# LPC865 register map
Vendor: nxp.com; File version: 1.0
CPU: CM0PLUS r0p0, little endian, no MPU, no FPU, VTOR, 2 interrupt priority bits
Registers are 32-bit, read-write, reset 0x0 unless marked. A register's access mark holds for its fields unless they carry their own. Offsets are from the block's base; [hi:lo] are bit positions.

## USART0 — LPC84x USARTs
Base 0x40064000
Same registers: USART1 0x40068000, USART2 0x4006C000
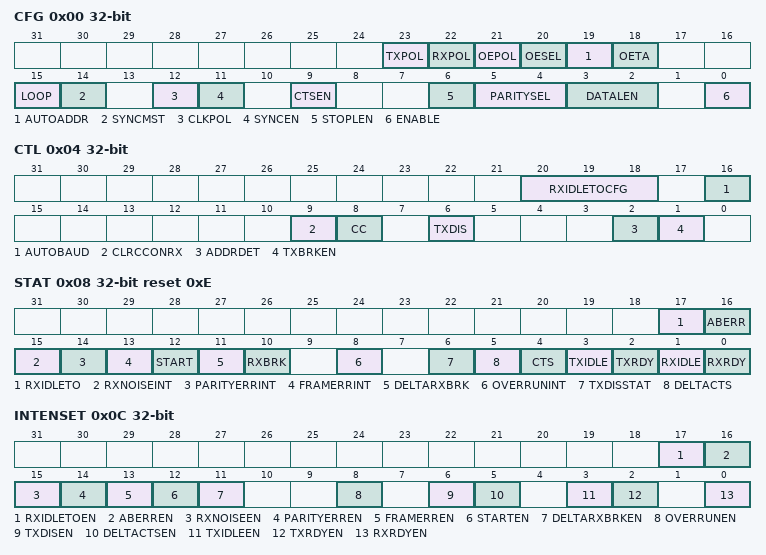
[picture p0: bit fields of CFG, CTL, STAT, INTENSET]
0x00 CFG — USART Configuration register. Basic USART configuration settings that typically are not changed during operation.
  [23] TXPOL — Transmit data polarity.
    0=STANDARD (Standard. The TX signal is sent out without change. This means that the TX rest value is 1, start bit is 0, data is not inverted, and the stop bit is 1.); 1=INVERTED (Inverted. The TX signal is inverted by the USART before being sent out. This means that the TX rest value is 0, start bit is 1, data is inverted, and the stop bit is 0.)
  [22] RXPOL — Receive data polarity.
    0=STANDARD (Standard. The RX signal is used as it arrives from the pin. This means that the RX rest value is 1, start bit is 0, data is not inverted, and the stop bit is 1.); 1=INVERTED (Inverted. The RX signal is inverted before being used by the USART. This means that the RX rest value is 0, start bit is 1, data is inverted, and the stop bit is 0.)
  [21] OEPOL — Output Enable Polarity.
    0=LOW (Low. If selected by OESEL, the output enable is active low.); 1=HIGH (High. If selected by OESEL, the output enable is active high.)
  [20] OESEL — Output Enable Select.
    0=STANDARD (Standard. The RTS signal is used as the standard flow control function.); 1=RS_485 (RS-485. The RTS signal configured to provide an output enable signal to control an RS-485 transceiver.)
  [19] AUTOADDR — Automatic Address matching enable.
    0=DISABLED (Disabled. When addressing is enabled by ADDRDET, address matching is done by software. This provides the possibility of versatile addressing (e.g. respond to more than one address).); 1=ENABLED (Enabled. When addressing is enabled by ADDRDET, address matching is done by hardware, using the value in the ADDR register as the address to match.)
  [18] OETA — Output Enable Turnaround time enable for RS-485 operation.
    0=DISABLED (Disabled. If selected by OESEL, the Output Enable signal deasserted at the end of the last stop bit of a transmission.); 1=ENABLED (Enabled. If selected by OESEL, the Output Enable signal remains asserted for one character time after the end of the last stop bit of a transmission. OE will also remain asserted if another transmit begins before it is deasserted.)
  [15] LOOP — Selects data loopback mode.
    0=NORMAL (Normal operation.); 1=LOOPBACK (Loopback mode. This provides a mechanism to perform diagnostic loopback testing for USART data. Serial data from the transmitter (Un_TXD) is connected internally to serial input of the receive (Un_RXD). Un_TXD and Un_RTS activity will also appear on external pins if these functions are configured to appear on device pins. The receiver RTS signal is also looped back to CTS and performs flow control if enabled by CTSEN.)
  [14] SYNCMST — Synchronous mode Master select.
    0=SLAVE (Slave. When synchronous mode is enabled, the USART is a slave.); 1=MASTER (Master. When synchronous mode is enabled, the USART is a master.)
  [12] CLKPOL — Selects the clock polarity and sampling edge of received data in synchronous mode.
    0=FALLING_EDGE (Falling edge. Un_RXD is sampled on the falling edge of SCLK.); 1=RISING_EDGE (Rising edge. Un_RXD is sampled on the rising edge of SCLK.)
  [11] SYNCEN — Selects synchronous or asynchronous operation.
    0=ASYNCHRONOUS_MODE; 1=SYNCHRONOUS_MODE
  [9] CTSEN — CTS Enable. Determines whether CTS is used for flow control. CTS can be from the input pin, or from the USART's own RTS if loopback mode is enabled.
    0=DISABLED (No flow control. The transmitter does not receive any automatic flow control signal.); 1=ENABLED (Flow control enabled. The transmitter uses the CTS input (or RTS output in loopback mode) for flow control purposes.)
  [6] STOPLEN — Number of stop bits appended to transmitted data. Only a single stop bit is required for received data.
    0=BIT_1 (1 stop bit.); 1=BITS_2 (2 stop bits. This setting should only be used for asynchronous communication.)
  [5:4] PARITYSEL — Selects what type of parity is used by the USART.
    0=NO_PARITY; 2=EVEN_PARITY (Even parity. Adds a bit to each character such that the number of 1s in a transmitted character is even, and the number of 1s in a received character is expected to be even.); 3=ODD_PARITY (Odd parity. Adds a bit to each character such that the number of 1s in a transmitted character is odd, and the number of 1s in a received character is expected to be odd.)
  [3:2] DATALEN — Selects the data size for the USART.
    0=BIT_7 (7 bit Data length.); 1=BIT_8 (8 bit Data length.); 2=BIT_9 (9 bit data length. The 9th bit is commonly used for addressing in multidrop mode. See the ADDRDET bit in the CTL register.)
  [0] ENABLE — USART Enable.
    0=DISABLED (Disabled. The USART is disabled and the internal state machine and counters are reset. While Enable = 0, all USART interrupts and DMA transfers are disabled. When Enable is set again, CFG and most other control bits remain unchanged. When re-enabled, the USART will immediately be ready to transmit because the transmitter has been reset and is therefore available.); 1=ENABLED (Enabled. The USART is enabled for operation.)
0x04 CTL (reset mask 0x10346) — USART Control register. USART control settings that are more likely to change during operation.
  [20:18] RXIDLETOCFG — RX IDLE time out configuration
    0=id0 (000b - 1 idle character); 1=id1 (001b - 2 idle characters); 2=id2 (010b - 4 idle characters); 3=id3 (011b - 8 idle characters); 4=id4 (100b - 16 idle characters); 5=id5 (101b - 32 idle characters); 6=id6 (110b - 64 idle characters); 7=id7 (111b - 128 idle characters)
  [16] AUTOBAUD — Autobaud enable.
    0=DISABLED (Disabled. USART is in normal operating mode.); 1=ENABLED (Enabled. USART is in autobaud mode. This bit should only be set when the USART receiver is idle. The first start bit of RX is measured and used the update the BRG register to match the received data rate. AUTOBAUD is cleared once this process is complete, or if there is an AERR.)
  [9] CLRCCONRX — Clear Continuous Clock.
    0=NO_EFFECT (No effect. No effect on the CC bit.); 1=AUTO_CLEAR (Auto-clear. The CC bit is automatically cleared when a complete character has been received. This bit is cleared at the same time.)
  [8] CC — Continuous Clock generation. By default, SCLK is only output while data is being transmitted in synchronous mode.
    0=CLOCK_ON_CHARACTER (Clock on character. In synchronous mode, SCLK cycles only when characters are being sent on Un_TXD or to complete a character that is being received.); 1=CONTINOUS_CLOCK (Continuous clock. SCLK runs continuously in synchronous mode, allowing characters to be received on Un_RxD independently from transmission on Un_TXD).)
  [6] TXDIS — Transmit Disable.
    0=ENABLED (Not disabled. USART transmitter is not disabled.); 1=DISABLED (Disabled. USART transmitter is disabled after any character currently being transmitted is complete. This feature can be used to facilitate software flow control.)
  [2] ADDRDET — Enable address detect mode.
    0=DISABLED (Disabled. The USART presents all incoming data.); 1=ENABLED (Enabled. The USART receiver ignores incoming data that does not have the most significant bit of the data (typically the 9th bit) = 1. When the data MSB bit = 1, the receiver treats the incoming data normally, generating a received data interrupt. Software can then check the data to see if this is an address that should be handled. If it is, the ADDRDET bit is cleared by software and further incoming data is handled normally.)
  [1] TXBRKEN — Break Enable.
    0=NORMAL (Normal operation.); 1=CONTINOUS (Continuous break. Continuous break is sent immediately when this bit is set, and remains until this bit is cleared. A break may be sent without danger of corrupting any currently transmitting character if the transmitter is first disabled (TXDIS in CTL is set) and then waiting for the transmitter to be disabled (TXDISINT in STAT = 1) before writing 1 to TXBRKEN.)
0x08 STAT reset 0xE (reset mask 0x1FD7F) — USART Status register. The complete status value can be read here. Writing ones clears some bits in the register. Some bits can be cleared by writing a 1 to them.
  [17] RXIDLETO — RX IDLE Timeout flag. Set when the receiver has been idle for a certain period of time as specified by CTRL.RXIDLETOCFG. Writing 1 clears this bit and lowers the corresponding interrupt. Once cleared, it cannot be set again until after the receiver receives a new character (non-idle).
  [16] ABERR — Autobaud Error. An autobaud error can occur if the BRG counts to its limit before the end of the start bit that is being measured, essentially an autobaud time-out.
  [15] RXNOISEINT — Received Noise interrupt flag. Three samples of received data are taken in order to determine the value of each received data bit, except in synchronous mode. This acts as a noise filter if one sample disagrees. This flag is set when a received data bit contains one disagreeing sample. This could indicate line noise, a baud rate or character format mismatch, or loss of synchronization during data reception.
  [14] PARITYERRINT — Parity Error interrupt flag. This flag is set when a parity error is detected in a received character.
  [13] FRAMERRINT — Framing Error interrupt flag. This flag is set when a character is received with a missing stop bit at the expected location. This could be an indication of a baud rate or configuration mismatch with the transmitting source.
  [12] START — This bit is set when a start is detected on the receiver input. Its purpose is primarily to allow wake-up from Deep-sleep or Power-down mode immediately when a start is detected. Cleared by software.
  [11] DELTARXBRK — This bit is set when a change in the state of receiver break detection occurs.Cleared by software.
  [10] RXBRK ro — Received Break. This bit reflects the current state of the receiver break detection logic. It is set when the Un_RXD pin remains low for 16 bit times. Note that FRAMERRINT will also be set when this condition occurs because the stop bit(s) for the character would be missing. RXBRK is cleared when the Un_RXD pin goes high.
  [8] OVERRUNINT — Overrun Error interrupt flag. This flag is set when a new character is received while the receiver buffer is still in use. If this occurs, the newly received character in the shift register is lost.
  [6] TXDISSTAT ro — Transmitter Disabled Interrupt flag. When 1, this bit indicates that the USART transmitter is fully idle after being disabled via the TXDIS in the CTL register (TXDIS = 1).
  [5] DELTACTS — This bit is set when a change in the state is detected for the CTS flag above. This bit is cleared by software.
  [4] CTS ro — This bit reflects the current state of the CTS signal, regardless of the setting of the CTSEN bit in the CFG register. This will be the value of the CTS input pin unless loopback mode is enabled.
  [3] TXIDLE ro — Transmitter Idle. When 0, indicates that the transmitter is currently in the process of sending data.When 1, indicate that the transmitter is not currently in the process of sending data.
  [2] TXRDY ro — Transmitter Ready flag. When 1, this bit indicates that data may be written to the transmit buffer. Previous data may still be in the process of being transmitted. Cleared when data is written to TXDAT. Set when the data is moved from the transmit buffer to the transmit shift register.
  [1] RXIDLE ro — Receiver Idle. When 0, indicates that the receiver is currently in the process of receiving data. When 1, indicates that the receiver is not currently in the process of receiving data.
  [0] RXRDY ro — Receiver Ready flag. When 1, indicates that data is available to be read from the receiver buffer. Cleared after a read of the RXDAT or RXDATSTAT registers.
0x0C INTENSET (reset mask 0x1F96D) — Interrupt Enable read and Set register. Contains an individual interrupt enable bit for each potential USART interrupt. A complete value may be read from this register. Writing a 1 to any implemented bit position causes that bit to be set.
  [17] RXIDLETOEN — RX IDLE timeout interrupt enable. Write 1 to set the bit. Writing 0 has no effect. 0: RX IDLE time out interrupt is disabled. 1: When STAT.RXIDLETO is set, interrupt is asserted.
  [16] ABERREN — When 1, enables an interrupt when an autobaud error occurs.
  [15] RXNOISEEN — When 1, enables an interrupt when noise is detected.
  [14] PARITYERREN — When 1, enables an interrupt when a parity error has been detected.
  [13] FRAMERREN — When 1, enables an interrupt when a framing error has been detected.
  [12] STARTEN — When 1, enables an interrupt when a received start bit has been detected.
  [11] DELTARXBRKEN — When 1, enables an interrupt when a change of state has occurred in the detection of a received break condition (break condition asserted or deasserted).
  [8] OVERRUNEN — When 1, enables an interrupt when an overrun error occurred.
  [6] TXDISEN — When 1, enables an interrupt when the transmitter is fully disabled as indicated by the TXDISINT flag in STAT. See description of the TXDISINT bit for details.
  [5] DELTACTSEN — When 1, enables an interrupt when there is a change in the state of the CTS input.
  [3] TXIDLEEN — When 1, enables an interrupt when the transmitter becomes idle (TXIDLE = 1).
  [2] TXRDYEN — When 1, enables an interrupt when the TXDAT register is available to take another character to transmit.
  [0] RXRDYEN — When 1, enables an interrupt when there is a received character available to be read from the RXDAT register.
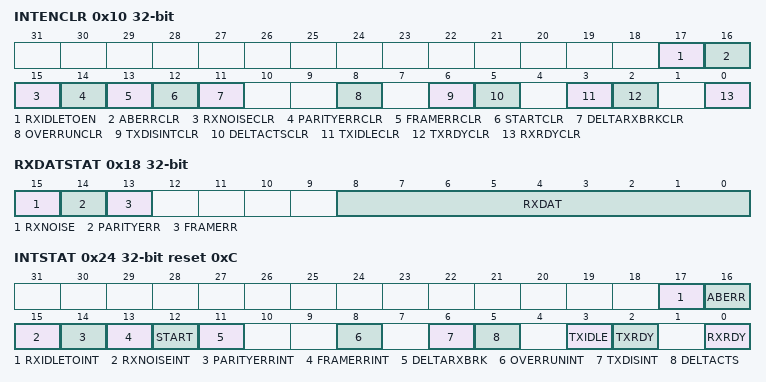
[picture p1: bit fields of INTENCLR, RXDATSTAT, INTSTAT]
0x10 INTENCLR wo reset not defined — Interrupt Enable Clear register. Allows clearing any combination of bits in the INTENSET register. Writing a 1 to any implemented bit position causes the corresponding bit to be cleared.
  [17] RXIDLETOEN — Writing 1 to clears INTENSET[RXIDLETOEN]. Writing 0 has no effect. The access for this bit is write-only.
  [16] ABERRCLR — Writing 1 clears the corresponding bit in the INTENSET register.
  [15] RXNOISECLR — Writing 1 clears the corresponding bit in the INTENSET register.
  [14] PARITYERRCLR — Writing 1 clears the corresponding bit in the INTENSET register.
  [13] FRAMERRCLR — Writing 1 clears the corresponding bit in the INTENSET register.
  [12] STARTCLR — Writing 1 clears the corresponding bit in the INTENSET register.
  [11] DELTARXBRKCLR — Writing 1 clears the corresponding bit in the INTENSET register.
  [8] OVERRUNCLR — Writing 1 clears the corresponding bit in the INTENSET register.
  [6] TXDISINTCLR — Writing 1 clears the corresponding bit in the INTENSET register.
  [5] DELTACTSCLR — Writing 1 clears the corresponding bit in the INTENSET register.
  [3] TXIDLECLR — Writing 1 clears the corresponding bit in the INTENSET register.
  [2] TXRDYCLR — Writing 1 clears the corresponding bit in the INTENSET register.
  [0] RXRDYCLR — Writing 1 clears the corresponding bit in the INTENSET register.
0x14 RXDAT ro reset not defined — Receiver Data register. Contains the last character received.
  [8:0] RXDAT — The USART Receiver Data register contains the next received character. The number of bits that are relevant depends on the USART configuration settings.
0x18 RXDATSTAT ro reset not defined — Receiver Data with Status register. Combines the last character received with the current USART receive status. Allows DMA or software to recover incoming data and status together.
  [15] RXNOISE — Received Noise flag.
  [14] PARITYERR — Parity Error status flag. This bit is valid when there is a character to be read in the RXDAT register and reflects the status of that character. This bit will be set when a parity error is detected in a received character.
  [13] FRAMERR — Framing Error status flag. This bit is valid when there is a character to be read in the RXDAT register and reflects the status of that character. This bit will set when the character in RXDAT was received with a missing stop bit at the expected location. This could be an indication of a baud rate or configuration mismatch with the transmitting source.
  [8:0] RXDAT — The USART Receiver Data register contains the next received character. The number of bits that are relevant depends on the USART configuration settings.
0x1C TXDAT — Transmit Data register. Data to be transmitted is written here.
  [8:0] TXDAT — Writing to the USART Transmit Data Register causes the data to be transmitted as soon as the transmit shift register is available and any conditions for transmitting data are met: CTS low (if CTSEN bit = 1), TXDIS bit = 0.
0x20 BRG — Baud Rate Generator register. 16-bit integer baud rate divisor value.
  [15:0] BRGVAL — This value is used to divide the USART input clock to determine the baud rate, based on the input clock from the FRG. 0 = FCLK is used directly by the USART function. 1 = FCLK is divided by 2 before use by the USART function. 2 = FCLK is divided by 3 before use by the USART function. 0xFFFF = FCLK is divided by 65,536 before use by the USART function.
0x24 INTSTAT reset 0xC (reset mask 0x1F96D) — Interrupt status register. Reflects interrupts that are currently enabled.
  [17] RXIDLETOINT ro — RX IDLE timeout interrupt flag. The access of this bit is read-only.
  [16] ABERR ro — Autobaud Error flag.
  [15] RXNOISEINT ro — Received Noise interrupt flag.
  [14] PARITYERRINT ro — Parity Error interrupt flag.
  [13] FRAMERRINT ro — Framing Error interrupt flag.
  [12] START ro — This bit is set when a start is detected on the receiver input.
  [11] DELTARXBRK ro — This bit is set when a change in the state of receiver break detection occurs.
  [8] OVERRUNINT ro — Overrun Error interrupt flag.
  [6] TXDISINT ro — Transmitter Disabled Interrupt flag.
  [5] DELTACTS ro — This bit is set when a change in the state of the CTS input is detected.
  [3] TXIDLE ro — Transmitter idle status.
  [2] TXRDY ro — Transmitter Ready flag.
  [0] RXRDY ro — Receiver Ready flag.
0x28 OSR reset 0xF — Oversample selection register for asynchronous communication.
  [3:0] OSRVAL — Oversample Selection Value. 0 to 3 = not supported 0x4 = 5 function clocks are used to transmit and receive each data bit. 0x5 = 6 function clocks are used to transmit and receive each data bit. 0xF= 16 function clocks are used to transmit and receive each data bit.
0x2C ADDR — Address register for automatic address matching.
  [7:0] ADDRESS — 8-bit address used with automatic address matching. Used when address detection is enabled (ADDRDET in CTL = 1) and automatic address matching is enabled (AUTOADDR in CFG = 1).
